AUTOSAR XML (schema 4-2-2)
package /swc
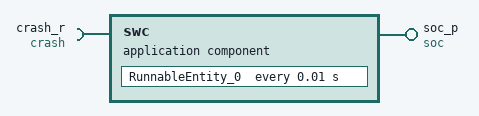
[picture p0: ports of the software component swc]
  application sw component type swc
    provide port soc_p: provided-interface=soc
    require port crash_r: required-interface=crash
    behavior swc
      timing event TimingEvent_10ms: start-on-event=RunnableEntity_0, period=0.01
      runnable RunnableEntity_0: symbol=RunnableEntity_swc_func
        data-read-access:
          access DRA_DataElements_VariableDataPrototype_0_0: accessed-variable=crash_r.DataElements_VariableDataPrototype_0
        data-write-access:
          access DWA_DataElements_VariableDataPrototype_0_0: accessed-variable=soc_p.DataElements_VariableDataPrototype_0
